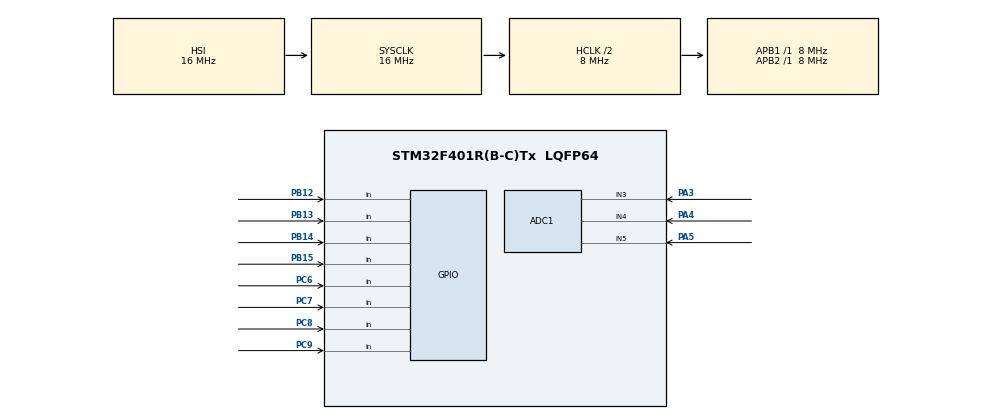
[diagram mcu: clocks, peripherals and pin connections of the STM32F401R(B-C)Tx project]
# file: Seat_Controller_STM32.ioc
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ADC1.Channel-0\#ChannelRegularConversion=ADC_CHANNEL_3
ADC1.NbrOfConversionFlag=1
ADC1.Rank-0\#ChannelRegularConversion=1
ADC1.SamplingTime-0\#ChannelRegularConversion=ADC_SAMPLETIME_3CYCLES
ADC1.master=1
FREERTOS.Tasks01=defaultTask,24,128,StartDefaultTask,Default,NULL,Dynamic,NULL,NULL
FREERTOS.configENABLE_FPU=0
FREERTOS.configUSE_NEWLIB_REENTRANT=0
Mcu.Family=STM32F4
Mcu.Name=STM32F401R(B-C)Tx
Mcu.Package=LQFP64
NVIC.PriorityGroup=NVIC_PRIORITYGROUP_4
PA3.Signal=ADCx_IN3
PA4.Signal=ADCx_IN4
PA5.Signal=ADCx_IN5
PA6.Signal=SPI1_MISO
PA7.Signal=SPI1_MOSI
PB12.Signal=GPIO_Input
PB13.Signal=GPIO_Input
PB14.Signal=GPIO_Input
PB15.Signal=GPIO_Input
PB3.Signal=SPI1_SCK
PB6.Signal=I2C1_SCL
PB7.Signal=I2C1_SDA
PC6.Signal=GPIO_Input
PC7.Signal=GPIO_Input
PC8.Signal=GPIO_Input
PC9.Signal=GPIO_Input
ProjectManager.HeapSize=0x200
ProjectManager.StackSize=0x400
ProjectManager.TargetToolchain=STM32CubeIDE
RCC.AHBCLKDivider=RCC_SYSCLK_DIV2
RCC.AHBFreq_Value=8000000
RCC.APB1Freq_Value=8000000
RCC.APB1TimFreq_Value=8000000
RCC.APB2Freq_Value=8000000
RCC.APB2TimFreq_Value=8000000
RCC.CortexFreq_Value=8000000
RCC.HCLKFreq_Value=8000000
RCC.HSE_VALUE=25000000
RCC.HSI_VALUE=16000000
RCC.LSE_VALUE=32768
RCC.SYSCLKFreq_VALUE=16000000
RCC.VCOOutputFreq_Value=192000000
SH.ADCx_IN3.0=ADC1_IN3,IN3
SH.ADCx_IN4.0=ADC1_IN4,IN4
SH.ADCx_IN5.0=ADC1_IN5,IN5
VP_FREERTOS_VS_CMSIS_V2.Mode=CMSIS_V2
board=custom

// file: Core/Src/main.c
/* USER CODE BEGIN Header */
/**
  ******************************************************************************
  * @file           : main.c
  * @brief          : Main program body
  ******************************************************************************
  * @attention
  *
  * Copyright (c) 2025 STMicroelectronics.
  * All rights reserved.
  *
  * This software is licensed under terms that can be found in the LICENSE file
  * in the root directory of this software component.
  * If no LICENSE file comes with this software, it is provided AS-IS.
  *
  ******************************************************************************
  */
/* USER CODE END Header */
#include "main.h"
#include "cmsis_os.h"

ADC_HandleTypeDef hadc1;

/* Definitions for defaultTask */
osThreadId_t defaultTaskHandle;
const osThreadAttr_t defaultTask_attributes = {
  .name = "defaultTask",
  .stack_size = 128 * 4,
  .priority = (osPriority_t) osPriorityNormal,
};

void SystemClock_Config(void);
static void MX_GPIO_Init(void);
static void MX_ADC1_Init(void);
void StartDefaultTask(void *argument);

int main(void)
{

  /* MCU Configuration--------------------------------------------------------*/

  /* Reset of all peripherals, Initializes the Flash interface and the Systick. */
  HAL_Init();

  /* Configure the system clock */
  SystemClock_Config();

  /* Initialize all configured peripherals */
  MX_GPIO_Init();
  MX_ADC1_Init();

  /* Init scheduler */
  osKernelInitialize();

  /* Create the thread(s) */
  /* creation of defaultTask */
  defaultTaskHandle = osThreadNew(StartDefaultTask, NULL, &defaultTask_attributes);

  /* Start scheduler */
  osKernelStart();

  /* We should never get here as control is now taken by the scheduler */

  /* Infinite loop */
  while (1)
  {

  }
}

void SystemClock_Config(void)
{
  RCC_OscInitTypeDef RCC_OscInitStruct = {0};
  RCC_ClkInitTypeDef RCC_ClkInitStruct = {0};

  /** Configure the main internal regulator output voltage
  */
  __HAL_RCC_PWR_CLK_ENABLE();
  __HAL_PWR_VOLTAGESCALING_CONFIG(PWR_REGULATOR_VOLTAGE_SCALE2);

  /** Initializes the RCC Oscillators according to the specified parameters
  * in the RCC_OscInitTypeDef structure.
  */
  RCC_OscInitStruct.OscillatorType = RCC_OSCILLATORTYPE_HSI;
  RCC_OscInitStruct.HSIState = RCC_HSI_ON;
  RCC_OscInitStruct.HSICalibrationValue = RCC_HSICALIBRATION_DEFAULT;
  RCC_OscInitStruct.PLL.PLLState = RCC_PLL_NONE;
  if (HAL_RCC_OscConfig(&RCC_OscInitStruct) != HAL_OK)
  {
    Error_Handler();
  }

  /** Initializes the CPU, AHB and APB buses clocks
  */
  RCC_ClkInitStruct.ClockType = RCC_CLOCKTYPE_HCLK|RCC_CLOCKTYPE_SYSCLK
                              |RCC_CLOCKTYPE_PCLK1|RCC_CLOCKTYPE_PCLK2;
  RCC_ClkInitStruct.SYSCLKSource = RCC_SYSCLKSOURCE_HSI;
  RCC_ClkInitStruct.AHBCLKDivider = RCC_SYSCLK_DIV2;
  RCC_ClkInitStruct.APB1CLKDivider = RCC_HCLK_DIV1;
  RCC_ClkInitStruct.APB2CLKDivider = RCC_HCLK_DIV1;

  if (HAL_RCC_ClockConfig(&RCC_ClkInitStruct, FLASH_LATENCY_0) != HAL_OK)
  {
    Error_Handler();
  }
}

static void MX_ADC1_Init(void)
{

  ADC_ChannelConfTypeDef sConfig = {0};

  /** Configure the global features of the ADC (Clock, Resolution, Data Alignment and number of conversion)
  */
  hadc1.Instance = ADC1;
  hadc1.Init.ClockPrescaler = ADC_CLOCK_SYNC_PCLK_DIV2;
  hadc1.Init.Resolution = ADC_RESOLUTION_12B;
  hadc1.Init.ScanConvMode = DISABLE;
  hadc1.Init.ContinuousConvMode = DISABLE;
  hadc1.Init.DiscontinuousConvMode = DISABLE;
  hadc1.Init.ExternalTrigConvEdge = ADC_EXTERNALTRIGCONVEDGE_NONE;
  hadc1.Init.ExternalTrigConv = ADC_SOFTWARE_START;
  hadc1.Init.DataAlign = ADC_DATAALIGN_RIGHT;
  hadc1.Init.NbrOfConversion = 1;
  hadc1.Init.DMAContinuousRequests = DISABLE;
  hadc1.Init.EOCSelection = ADC_EOC_SINGLE_CONV;
  if (HAL_ADC_Init(&hadc1) != HAL_OK)
  {
    Error_Handler();
  }

  /** Configure for the selected ADC regular channel its corresponding rank in the sequencer and its sample time.
  */
  sConfig.Channel = ADC_CHANNEL_3;
  sConfig.Rank = 1;
  sConfig.SamplingTime = ADC_SAMPLETIME_3CYCLES;
  if (HAL_ADC_ConfigChannel(&hadc1, &sConfig) != HAL_OK)
  {
    Error_Handler();
  }

}

static void MX_GPIO_Init(void)
{
  GPIO_InitTypeDef GPIO_InitStruct = {0};

  /* GPIO Ports Clock Enable */
  __HAL_RCC_GPIOA_CLK_ENABLE();
  __HAL_RCC_GPIOB_CLK_ENABLE();
  __HAL_RCC_GPIOC_CLK_ENABLE();

  /*Configure GPIO pins : PA6 PA7 */
  GPIO_InitStruct.Pin = GPIO_PIN_6|GPIO_PIN_7;
  GPIO_InitStruct.Mode = GPIO_MODE_AF_PP;
  GPIO_InitStruct.Pull = GPIO_NOPULL;
  GPIO_InitStruct.Speed = GPIO_SPEED_FREQ_VERY_HIGH;
  GPIO_InitStruct.Alternate = GPIO_AF5_SPI1;
  HAL_GPIO_Init(GPIOA, &GPIO_InitStruct);

  /*Configure GPIO pins : PB12 PB13 PB14 PB15 */
  GPIO_InitStruct.Pin = GPIO_PIN_12|GPIO_PIN_13|GPIO_PIN_14|GPIO_PIN_15;
  GPIO_InitStruct.Mode = GPIO_MODE_INPUT;
  GPIO_InitStruct.Pull = GPIO_NOPULL;
  HAL_GPIO_Init(GPIOB, &GPIO_InitStruct);

  /*Configure GPIO pins : PC6 PC7 PC8 PC9 */
  GPIO_InitStruct.Pin = GPIO_PIN_6|GPIO_PIN_7|GPIO_PIN_8|GPIO_PIN_9;
  GPIO_InitStruct.Mode = GPIO_MODE_INPUT;
  GPIO_InitStruct.Pull = GPIO_NOPULL;
  HAL_GPIO_Init(GPIOC, &GPIO_InitStruct);

  /*Configure GPIO pin : PB3 */
  GPIO_InitStruct.Pin = GPIO_PIN_3;
  GPIO_InitStruct.Mode = GPIO_MODE_AF_PP;
  GPIO_InitStruct.Pull = GPIO_NOPULL;
  GPIO_InitStruct.Speed = GPIO_SPEED_FREQ_VERY_HIGH;
  GPIO_InitStruct.Alternate = GPIO_AF5_SPI1;
  HAL_GPIO_Init(GPIOB, &GPIO_InitStruct);

  /*Configure GPIO pins : PB6 PB7 */
  GPIO_InitStruct.Pin = GPIO_PIN_6|GPIO_PIN_7;
  GPIO_InitStruct.Mode = GPIO_MODE_AF_OD;
  GPIO_InitStruct.Pull = GPIO_NOPULL;
  GPIO_InitStruct.Speed = GPIO_SPEED_FREQ_VERY_HIGH;
  GPIO_InitStruct.Alternate = GPIO_AF4_I2C1;
  HAL_GPIO_Init(GPIOB, &GPIO_InitStruct);

}

void StartDefaultTask(void *argument)
{
  for(;;)
  {
    osDelay(1);
  }
}

void Error_Handler(void)
{
  __disable_irq();
  while (1)
  {
  }
}

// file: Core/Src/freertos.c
/* USER CODE BEGIN Header */
/**
  ******************************************************************************
  * File Name          : freertos.c
  * Description        : Code for freertos applications
  ******************************************************************************
  * @attention
  *
  * Copyright (c) 2025 STMicroelectronics.
  * All rights reserved.
  *
  * This software is licensed under terms that can be found in the LICENSE file
  * in the root directory of this software component.
  * If no LICENSE file comes with this software, it is provided AS-IS.
  *
  ******************************************************************************
  */
/* USER CODE END Header */

#include "FreeRTOS.h"
#include "task.h"
#include "main.h"

/* USER CODE BEGIN Includes */

typedef enum
{
	MANUL_MODE = 0,
	Automatic_Mode,
}Mode_Selection_t;

/*Default Mode of the Car Seat*/
Mode_Selection_t DefaultMode = MANUL_MODE;

/* USER CODE END Includes */
